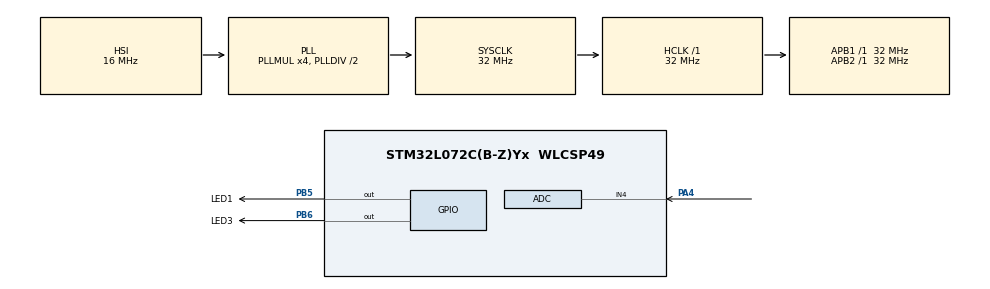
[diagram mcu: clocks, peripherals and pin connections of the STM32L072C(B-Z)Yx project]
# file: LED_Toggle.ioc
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ADC.ClockPrescaler=ADC_CLOCK_SYNC_PCLK_DIV2
ADC.ContinuousConvMode=ENABLE
ADC.DMAContinuousRequests=ENABLE
ADC.DataAlign=ADC_DATAALIGN_RIGHT
ADC.DiscontinuousConvMode=DISABLE
ADC.EOCSelection=ADC_EOC_SEQ_CONV
ADC.EnableAnalogWatchDog=false
ADC.ExternalTrigConv=ADC_SOFTWARE_START
ADC.ExternalTrigConvEdge=ADC_EXTERNALTRIGCONVEDGE_NONE
ADC.LowPowerAutoPowerOff=DISABLE
ADC.LowPowerAutoWait=DISABLE
ADC.LowPowerFrequencyMode=DISABLE
ADC.Overrun=ADC_OVR_DATA_PRESERVED
ADC.OversamplingMode=DISABLE
ADC.Resolution=ADC_RESOLUTION_12B
ADC.SamplingTime=ADC_SAMPLETIME_160CYCLES_5
ADC.ScanConvMode=ADC_SCAN_DIRECTION_FORWARD
Dma.ADC.0.Direction=DMA_PERIPH_TO_MEMORY
Dma.ADC.0.Instance=DMA1_Channel1
Dma.ADC.0.MemDataAlignment=DMA_MDATAALIGN_HALFWORD
Dma.ADC.0.MemInc=DMA_MINC_ENABLE
Dma.ADC.0.Mode=DMA_CIRCULAR
Dma.ADC.0.PeriphDataAlignment=DMA_PDATAALIGN_HALFWORD
Dma.ADC.0.PeriphInc=DMA_PINC_DISABLE
Dma.ADC.0.Priority=DMA_PRIORITY_HIGH
Dma.Request0=ADC
Mcu.Family=STM32L0
Mcu.Name=STM32L072C(B-Z)Yx
Mcu.Package=WLCSP49
NVIC.DMA1_Channel1_IRQn=true\:0\:0\:false\:false\:true\:false
PA4.Mode=IN4
PA4.Signal=ADC_IN4
PB5.GPIO_Label=LED1
PB5.GPIO_PuPd=GPIO_PULLDOWN
PB5.Signal=GPIO_Output
PB6.GPIO_Label=LED3
PB6.GPIO_PuPd=GPIO_PULLDOWN
PB6.Signal=GPIO_Output
PH0-OSC_IN.Mode=HSE-External-Oscillator
PH0-OSC_IN.Signal=RCC_OSC_IN
PH1-OSC_OUT.Mode=HSE-External-Oscillator
PH1-OSC_OUT.Signal=RCC_OSC_OUT
ProjectManager.HeapSize=0x200
ProjectManager.StackSize=0x400
ProjectManager.TargetToolchain=TrueSTUDIO
RCC.AHBFreq_Value=32000000
RCC.APB1Freq_Value=32000000
RCC.APB1TimFreq_Value=32000000
RCC.APB2Freq_Value=32000000
RCC.APB2TimFreq_Value=32000000
RCC.HCLKFreq_Value=32000000
RCC.HSE_VALUE=8000000
RCC.HSI16_VALUE=16000000
RCC.HSI48_VALUE=48000000
RCC.HSI_VALUE=16000000
RCC.LSE_VALUE=32768
RCC.MSI_VALUE=2097000
RCC.PLLMUL=RCC_PLLMUL_4
RCC.SYSCLKFreq_VALUE=32000000
RCC.SYSCLKSource=RCC_SYSCLKSOURCE_PLLCLK
RCC.VCOOutputFreq_Value=64000000
board=custom

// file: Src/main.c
/**
  ******************************************************************************
  * @file           : main.c
  * @brief          : Main program body
  ******************************************************************************
  ** This notice applies to any and all portions of this file
  * that are not between comment pairs USER CODE BEGIN and
  * USER CODE END. Other portions of this file, whether
  * inserted by the user or by software development tools
  * are owned by their respective copyright owners.
  *
  * COPYRIGHT(c) 2018 STMicroelectronics
  *
  * Redistribution and use in source and binary forms, with or without modification,
  * are permitted provided that the following conditions are met:
  *   1. Redistributions of source code must retain the above copyright notice,
  *      this list of conditions and the following disclaimer.
  *   2. Redistributions in binary form must reproduce the above copyright notice,
  *      this list of conditions and the following disclaimer in the documentation
  *      and/or other materials provided with the distribution.
  *   3. Neither the name of STMicroelectronics nor the names of its contributors
  *      may be used to endorse or promote products derived from this software
  *      without specific prior written permission.
  *
  * THIS SOFTWARE IS PROVIDED BY THE COPYRIGHT HOLDERS AND CONTRIBUTORS "AS IS"
  * AND ANY EXPRESS OR IMPLIED WARRANTIES, INCLUDING, BUT NOT LIMITED TO, THE
  * IMPLIED WARRANTIES OF MERCHANTABILITY AND FITNESS FOR A PARTICULAR PURPOSE ARE
  * DISCLAIMED. IN NO EVENT SHALL THE COPYRIGHT HOLDER OR CONTRIBUTORS BE LIABLE
  * FOR ANY DIRECT, INDIRECT, INCIDENTAL, SPECIAL, EXEMPLARY, OR CONSEQUENTIAL
  * DAMAGES (INCLUDING, BUT NOT LIMITED TO, PROCUREMENT OF SUBSTITUTE GOODS OR
  * SERVICES; LOSS OF USE, DATA, OR PROFITS; OR BUSINESS INTERRUPTION) HOWEVER
  * CAUSED AND ON ANY THEORY OF LIABILITY, WHETHER IN CONTRACT, STRICT LIABILITY,
  * OR TORT (INCLUDING NEGLIGENCE OR OTHERWISE) ARISING IN ANY WAY OUT OF THE USE
  * OF THIS SOFTWARE, EVEN IF ADVISED OF THE POSSIBILITY OF SUCH DAMAGE.
  *
  ******************************************************************************
  */
#include "main.h"
#include "stm32l0xx_hal.h"
#include "adc.h"
#include "dma.h"
#include "gpio.h"

/* USER CODE BEGIN PV */
	uint16_t ADCxConvertedValue[1];

/* Private variables ---------------------------------------------------------*/

/* USER CODE END PV */

void SystemClock_Config(void);

/* USER CODE BEGIN PFP */
/* Private function prototypes -----------------------------------------------*/

/* USER CODE END PFP */

int main(void)
{

  /* MCU Configuration----------------------------------------------------------*/

  /* Reset of all peripherals, Initializes the Flash interface and the Systick. */
  HAL_Init();

  /* Configure the system clock */
  SystemClock_Config();

  /* Initialize all configured peripherals */
  MX_GPIO_Init();
  MX_DMA_Init();
  MX_ADC_Init();
  /* USER CODE BEGIN 2 */
  HAL_ADC_Start_DMA(&hadc,(uint32_t*)&ADCxConvertedValue,1);
  /* USER CODE END 2 */

  /* Infinite loop */
  while (1)
  {

  }

}

void SystemClock_Config(void)
{

  RCC_OscInitTypeDef RCC_OscInitStruct;
  RCC_ClkInitTypeDef RCC_ClkInitStruct;

    /**Configure the main internal regulator output voltage
    */
  __HAL_PWR_VOLTAGESCALING_CONFIG(PWR_REGULATOR_VOLTAGE_SCALE1);

    /**Initializes the CPU, AHB and APB busses clocks
    */
  RCC_OscInitStruct.OscillatorType = RCC_OSCILLATORTYPE_HSI;
  RCC_OscInitStruct.HSIState = RCC_HSI_ON;
  RCC_OscInitStruct.HSICalibrationValue = 16;
  RCC_OscInitStruct.PLL.PLLState = RCC_PLL_ON;
  RCC_OscInitStruct.PLL.PLLSource = RCC_PLLSOURCE_HSI;
  RCC_OscInitStruct.PLL.PLLMUL = RCC_PLLMUL_4;
  RCC_OscInitStruct.PLL.PLLDIV = RCC_PLLDIV_2;
  if (HAL_RCC_OscConfig(&RCC_OscInitStruct) != HAL_OK)
  {
    _Error_Handler(__FILE__, __LINE__);
  }

    /**Initializes the CPU, AHB and APB busses clocks
    */
  RCC_ClkInitStruct.ClockType = RCC_CLOCKTYPE_HCLK|RCC_CLOCKTYPE_SYSCLK
                              |RCC_CLOCKTYPE_PCLK1|RCC_CLOCKTYPE_PCLK2;
  RCC_ClkInitStruct.SYSCLKSource = RCC_SYSCLKSOURCE_PLLCLK;
  RCC_ClkInitStruct.AHBCLKDivider = RCC_SYSCLK_DIV1;
  RCC_ClkInitStruct.APB1CLKDivider = RCC_HCLK_DIV1;
  RCC_ClkInitStruct.APB2CLKDivider = RCC_HCLK_DIV1;

  if (HAL_RCC_ClockConfig(&RCC_ClkInitStruct, FLASH_LATENCY_1) != HAL_OK)
  {
    _Error_Handler(__FILE__, __LINE__);
  }

    /**Configure the Systick interrupt time
    */
  HAL_SYSTICK_Config(HAL_RCC_GetHCLKFreq()/1000);

    /**Configure the Systick
    */
  HAL_SYSTICK_CLKSourceConfig(SYSTICK_CLKSOURCE_HCLK);

  /* SysTick_IRQn interrupt configuration */
  HAL_NVIC_SetPriority(SysTick_IRQn, 0, 0);
}

void _Error_Handler(char *file, int line)
{
  while(1)
  {
  }
}

/************************ (C) COPYRIGHT STMicroelectronics *****END OF FILE****/
